# A31T51x register map
Vendor: ABOV Semiconductor Co., Ltd.; File version: 1.0
CPU: CM0PLUS r0p1, little endian, no MPU, no FPU, VTOR, 2 interrupt priority bits
Registers are 32-bit, read-write, reset 0x0 unless marked. A register's access mark holds for its fields unless they carry their own. Offsets are from the block's base; [hi:lo] are bit positions; {n}, {i} and the like mark numbered series.

## PORTRSTDBCR — General Port Reset Debounce Enable
Base 0x40090F0C
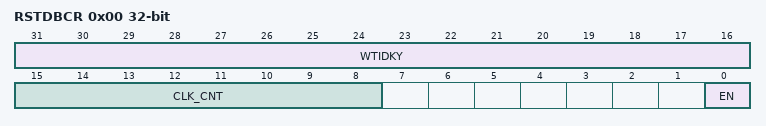
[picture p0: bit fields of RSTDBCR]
0x00 RSTDBCR — Port Reset Debounce Control Register
  [31:16] WTIDKY — Write Identification Key
  [15:8] CLK_CNT — Noise cancelling delay option for selected debounce clock
  [0] EN — Pin reset debounce enable
    0=Disable (Pin reset debounce diable); 1=Enable (Pin reset debounce enable)

## PORTEN — General Port Access Enable
Base 0x40090FF0
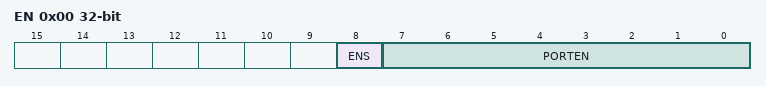
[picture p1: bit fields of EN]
0x00 EN wo — Port Access Enable Register
  [8] ENS ro — Pin Clear bit, x = 0 to 15
  [7:0] PORTEN — PCU and GPIO register access enable (0x15, 0x51)

## DFMC — DATA FLASH MEMORY CONTROLLER
Base 0x40081000
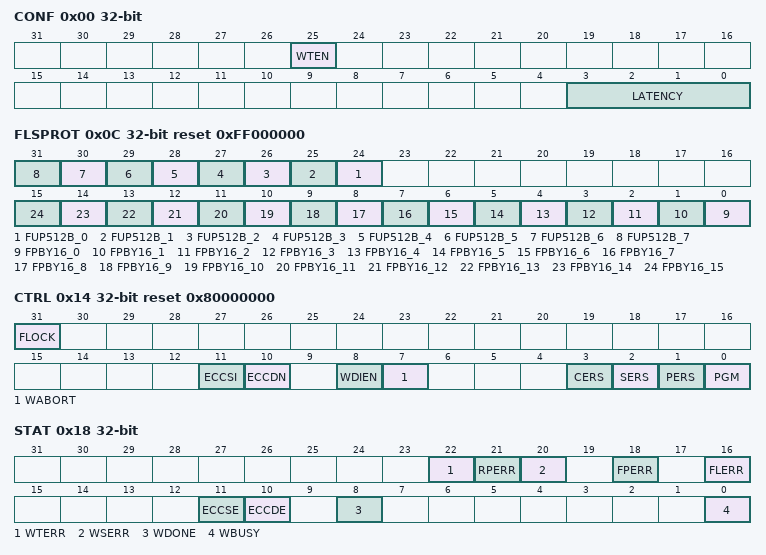
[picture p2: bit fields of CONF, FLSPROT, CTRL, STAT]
0x00 CONF — Data Flash Memory Config Register
  [25] WTEN — Whether to Enable or Disable the Data Flash Write
  [3:0] LATENCY — Flash Wait Value Bits
0x04 FLSKEY wo — Data Flash Memory Access Key Register
  [31:0] FKEY — Flash Memory Access Key, KEY1(0x01234567) -> KEY2(0x12345678) -> KEY3(0x23456789)
0x0C FLSPROT reset 0xFF000000 — Data Flash Memory Protection Register
  [n+24] FUP512B_{n} (n=0..7) — Flash upper 4KB Unprotection
  [n] FPBY16_{n} (n=0..15) — Flash 2KB Protection
0x14 CTRL reset 0x80000000 — Data Flash Access Control Register
  [31] FLOCK — Flash Memory Lock Bit
  [11] ECCSI — ECC single error interrupt enable
    0=Disable interrupt; 1=Enable interrupt
  [10] ECCDN — ECC double error non-maskable interrupt enable
    0=Disable interrupt; 1=Enable interrupt
  [8] WDIEN — Whether to Enable or Disable the Write Done Interrupt
    0=Disable interrupt; 1=Enable interrupt
  [7] WABORT — Abort write operation
    0=Disable (No Effect); 1=Enable (Abort write operaton)
  [3] CERS — Flash Memory Bulk(Chip) Erase Mode
    0=Disable bulk erase; 1=Enable bulk erase
  [2] SERS — Flash Memory Sector (2KB) Erase Mode
    0=Disable sector erase; 1=Enable sector erase
  [1] PERS — Flash Memory Page (512 Bytes) Erase Mode
    0=Disable page erase; 1=Enable page erase
  [0] PGM — Flash Memory Write Mode
    0=Disable write mode; 1=Enable write mode
0x18 STAT — Data Flash Access Status Register
  [22] WTERR — Wrtie Timeout Error (Cleared by writing a '1' )
  [21] RPERR — Read Protect Error (Cleared by writing a '1' )
  [20] WSERR — Write Sequence Error (Cleared by writing a '1' )
  [18] FPERR — Flash Protect Error (Cleared by writing a '1' )
  [16] FLERR — Flash Lock Error (Cleared by writing a '1' )
  [11] ECCSE — Code flash ECC single error (cleared by writing a '1')
  [10] ECCDE — Code flash ECC double error (cleared by writing a '1')
  [8] WDONE — Write Done Check (Cleared by writing a '1' )
  [0] WBUSY ro — Write Busy Check
    0=Not_Busy (Checksum Not Busy); 1=Busy (Checksum Busy)
0x40 WTIMEOUT — Data Flash Write Timeout Register
  [31:0] WTIMEOUT — Write timeout count
0x50 ECCEADDR — Data Flash ECC Error Address Register
  [31:0] ECCEA — ECC error address (Offset: 0x0E00_0000)
0x54 ECCEDATA — Data Flash ECC Error Data Register
  [31:0] ECCED — ECC error data (Offset: 0x0E00_0000)
0x58 ECCEPARITY — Data Flash Write Timeout Register
  [31:0] ECCEP — ECC error parity

## DMA — Direct Memory Access Control 0
Base 0x50000400
Same registers: DMA{n} {0x40000400+0x10*n} (n=0..7)
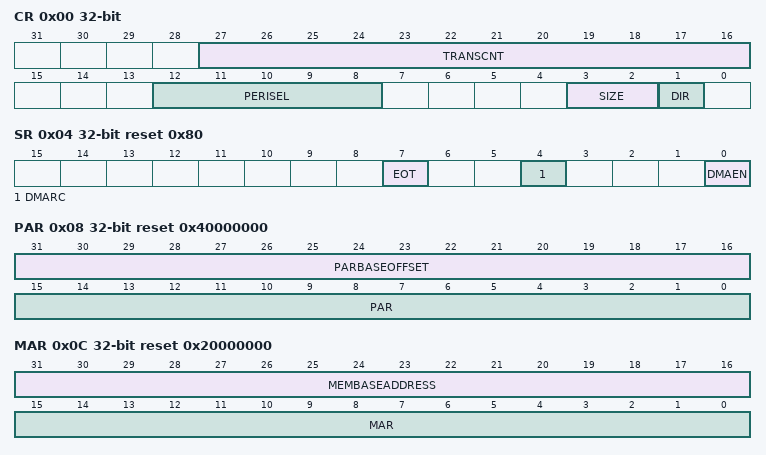
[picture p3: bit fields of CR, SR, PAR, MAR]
0x00 CR — DMA channel n control register
  [27:16] TRANSCNT — Number of DMA transfers Before enabling
  [12:8] PERISEL — Peripheral selection
  [3:2] SIZE — Bus transfer size
    0=Byte (transmit byte size); 1=half_word (transmit half word size); 2=word (transmit word size)
  [1] DIR — Transfer direction selection
    0=MEM-PERI (Memory->Peripheral); 1=PERI-MEM (Peripheral->Memory)
0x04 SR reset 0x80 — DMA channel n status register
  [7] EOT ro — Transfer ends
    0=BUSY (Transmit data is Busy); 1=EMPTY (Transmit complete)
  [4] DMARC — DMA request clear (Auto clear)
    1=Clear (DMA Clear)
  [0] DMAEN — Enables DMA use
0x08 PAR reset 0x40000000 — DMA channel n peripheral address register
  [31:16] PARBASEOFFSET ro — Peripheral base address offset
  [15:0] PAR — Address of the transfer / receive buffers target peripheral
0x0C MAR reset 0x20000000 — DMA channel n memory address register
  [31:16] MEMBASEADDRESS ro — Memory base address offset
  [15:0] MAR — Target memory address of the data transfer
